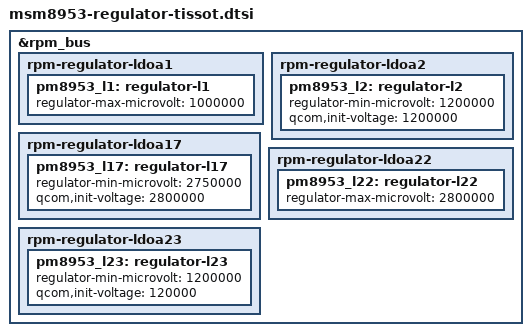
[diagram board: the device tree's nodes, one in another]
/*
 * Copyright (c) 2015-2016, The Linux Foundation. All rights reserved.
 *
 * This program is free software; you can redistribute it and/or modify
 * it under the terms of the GNU General Public License version 2 and
 * only version 2 as published by the Free Software Foundation.
 *
 * This program is distributed in the hope that it will be useful,
 * but WITHOUT ANY WARRANTY; without even the implied warranty of
 * MERCHANTABILITY or FITNESS FOR A PARTICULAR PURPOSE.  See the
 * GNU General Public License for more details.
 */

#include <dt-bindings/interrupt-controller/arm-gic.h>

&rpm_bus {
	rpm-regulator-ldoa1 {
		pm8953_l1: regulator-l1 {
			regulator-max-microvolt = <1000000>;
		};
	};

	rpm-regulator-ldoa2 {
		pm8953_l2: regulator-l2 {
			regulator-min-microvolt = <1200000>;
			qcom,init-voltage = <1200000>;
		};
	};

	rpm-regulator-ldoa17 {
		pm8953_l17: regulator-l17 {
			regulator-min-microvolt = <2750000>;
			qcom,init-voltage = <2800000>;
		};
	};

	rpm-regulator-ldoa22 {
		pm8953_l22: regulator-l22 {
			regulator-max-microvolt = <2800000>;
		};
	};

	rpm-regulator-ldoa23 {
		pm8953_l23: regulator-l23 {
			regulator-min-microvolt = <1200000>;
			qcom,init-voltage = <120000>;
		};
	};
};

